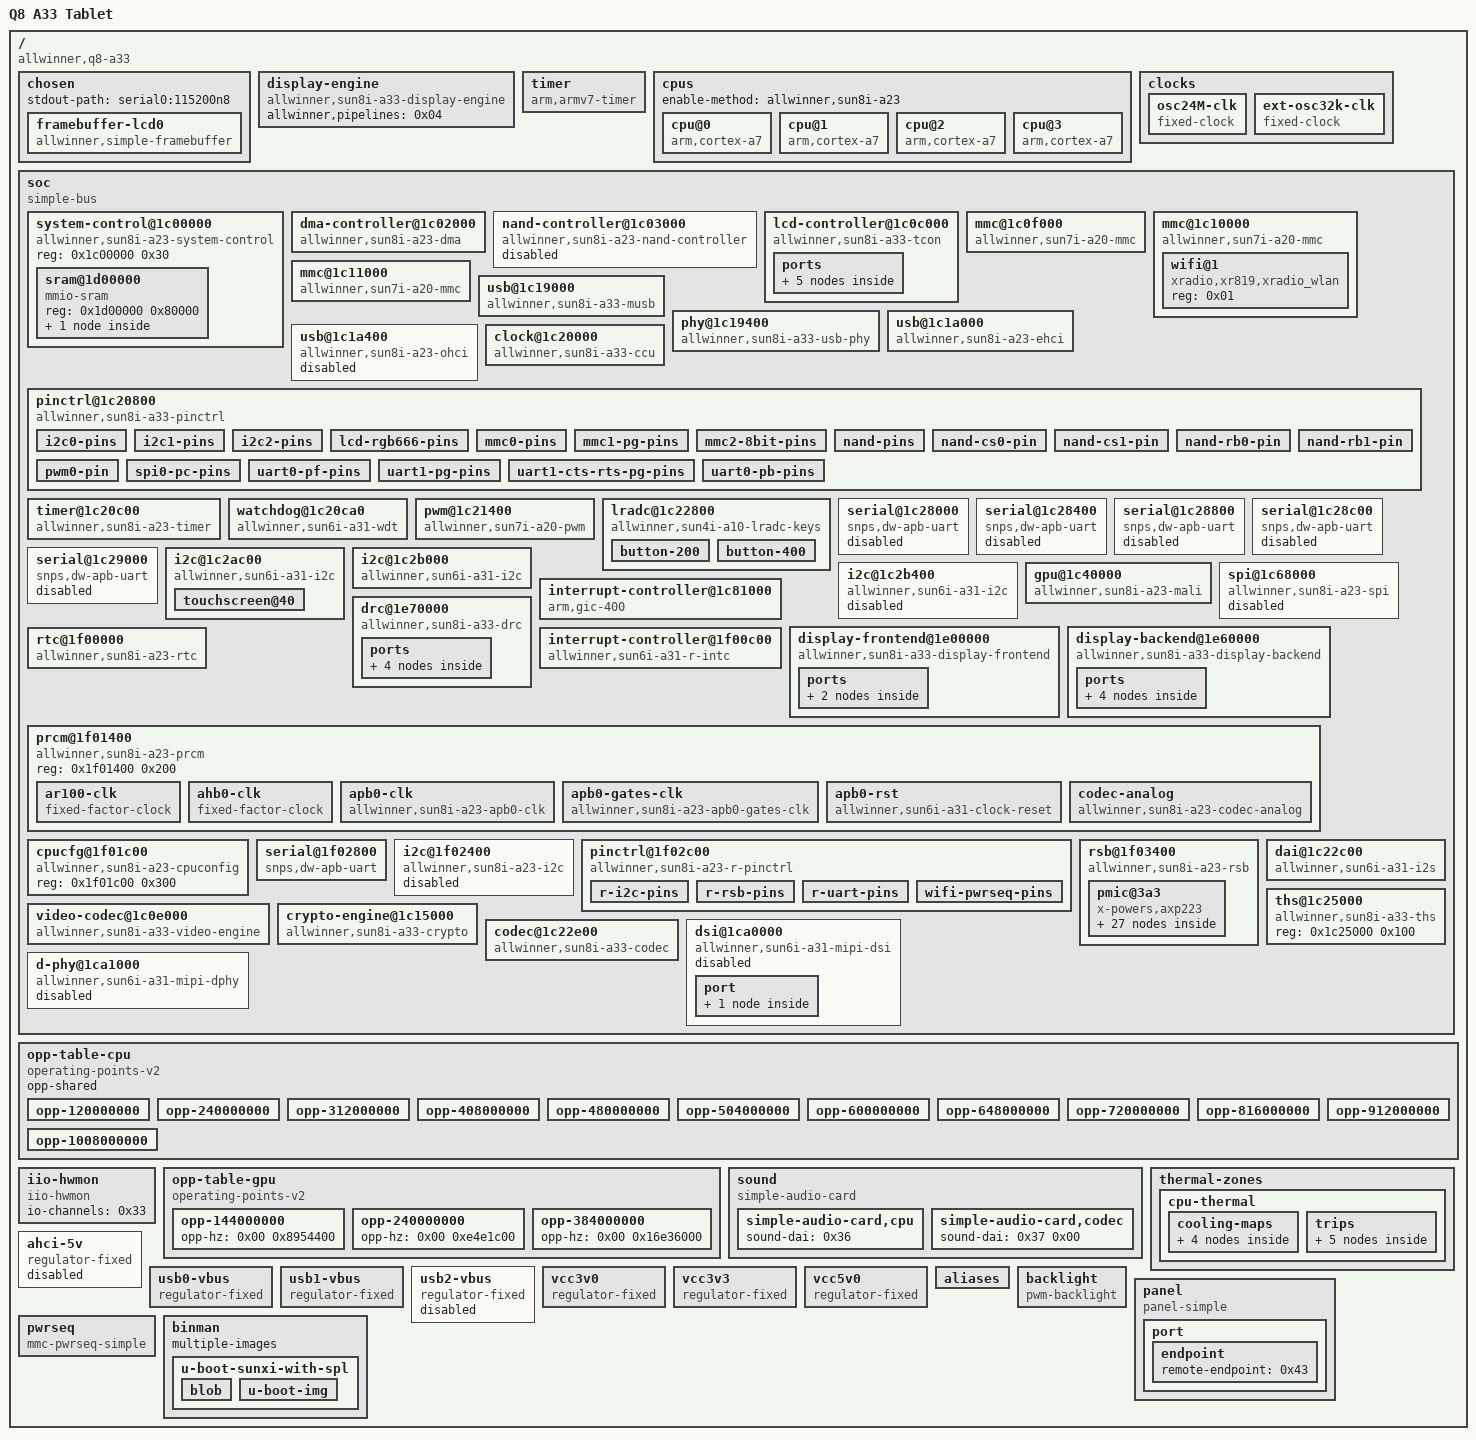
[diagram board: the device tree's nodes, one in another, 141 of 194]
/dts-v1/;

/ {
	interrupt-parent = <0x01>;
	#address-cells = <0x01>;
	#size-cells = <0x01>;
	model = "Q8 A33 Tablet";
	compatible = "allwinner,q8-a33", "allwinner,sun8i-a33";

	chosen {
		#address-cells = <0x01>;
		#size-cells = <0x01>;
		ranges;
		stdout-path = "serial0:115200n8";

		framebuffer-lcd0 {
			compatible = "allwinner,simple-framebuffer", "simple-framebuffer";
			allwinner,pipeline = "de_be0-lcd0";
			clocks = <0x02 0x26 0x02 0x28 0x02 0x57 0x02 0x55 0x02 0x54 0x02 0x62>;
			status = "okay";
			vcc-lcd-supply = <0x03>;
			phandle = <0x45>;
		};
	};

	display-engine {
		allwinner,pipelines = <0x04>;
		status = "okay";
		compatible = "allwinner,sun8i-a33-display-engine";
		phandle = <0x46>;
	};

	timer {
		compatible = "arm,armv7-timer";
		interrupts = <0x01 0x0d 0xf08 0x01 0x0e 0xf08 0x01 0x0b 0xf08 0x01 0x0a 0xf08>;
		clock-frequency = <0x16e3600>;
		arm,cpu-registers-not-fw-configured;
	};

	cpus {
		enable-method = "allwinner,sun8i-a23";
		#address-cells = <0x01>;
		#size-cells = <0x00>;

		cpu@0 {
			compatible = "arm,cortex-a7";
			device_type = "cpu";
			reg = <0x00>;
			clocks = <0x02 0x12>;
			clock-names = "cpu";
			operating-points-v2 = <0x05>;
			#cooling-cells = <0x02>;
			cpu-supply = <0x06>;
			phandle = <0x39>;
		};

		cpu@1 {
			compatible = "arm,cortex-a7";
			device_type = "cpu";
			reg = <0x01>;
			clocks = <0x02 0x12>;
			clock-names = "cpu";
			operating-points-v2 = <0x05>;
			#cooling-cells = <0x02>;
			phandle = <0x3a>;
		};

		cpu@2 {
			compatible = "arm,cortex-a7";
			device_type = "cpu";
			reg = <0x02>;
			clocks = <0x02 0x12>;
			clock-names = "cpu";
			operating-points-v2 = <0x05>;
			#cooling-cells = <0x02>;
			phandle = <0x3b>;
		};

		cpu@3 {
			compatible = "arm,cortex-a7";
			device_type = "cpu";
			reg = <0x03>;
			clocks = <0x02 0x12>;
			clock-names = "cpu";
			operating-points-v2 = <0x05>;
			#cooling-cells = <0x02>;
			phandle = <0x3c>;
		};
	};

	clocks {
		#address-cells = <0x01>;
		#size-cells = <0x01>;
		ranges;

		osc24M-clk {
			#clock-cells = <0x00>;
			compatible = "fixed-clock";
			clock-frequency = <0x16e3600>;
			clock-accuracy = <0xc350>;
			clock-output-names = "osc24M";
			phandle = <0x18>;
		};

		ext-osc32k-clk {
			#clock-cells = <0x00>;
			compatible = "fixed-clock";
			clock-frequency = <0x8000>;
			clock-accuracy = <0xc350>;
			clock-output-names = "ext-osc32k";
			phandle = <0x25>;
		};
	};

	soc {
		compatible = "simple-bus";
		#address-cells = <0x01>;
		#size-cells = <0x01>;
		ranges;

		system-control@1c00000 {
			compatible = "allwinner,sun8i-a23-system-control";
			reg = <0x1c00000 0x30>;
			#address-cells = <0x01>;
			#size-cells = <0x01>;
			ranges;

			sram@1d00000 {
				compatible = "mmio-sram";
				reg = <0x1d00000 0x80000>;
				#address-cells = <0x01>;
				#size-cells = <0x01>;
				ranges = <0x00 0x1d00000 0x80000>;
				phandle = <0x47>;

				sram-section@0 {
					compatible = "allwinner,sun8i-a23-sram-c1", "allwinner,sun4i-a10-sram-c1";
					reg = <0x00 0x80000>;
					phandle = <0x30>;
				};
			};
		};

		dma-controller@1c02000 {
			compatible = "allwinner,sun8i-a23-dma";
			reg = <0x1c02000 0x1000>;
			interrupts = <0x00 0x32 0x04>;
			clocks = <0x02 0x19>;
			resets = <0x02 0x06>;
			#dma-cells = <0x01>;
			phandle = <0x07>;
		};

		nand-controller@1c03000 {
			compatible = "allwinner,sun8i-a23-nand-controller";
			reg = <0x1c03000 0x1000>;
			interrupts = <0x00 0x46 0x04>;
			clocks = <0x02 0x1d 0x02 0x3b>;
			clock-names = "ahb", "mod";
			resets = <0x02 0x0a>;
			reset-names = "ahb";
			dmas = <0x07 0x05>;
			dma-names = "rxtx";
			pinctrl-names = "default";
			pinctrl-0 = <0x08 0x09 0x0a>;
			status = "disabled";
			#address-cells = <0x01>;
			#size-cells = <0x00>;
			phandle = <0x48>;
		};

		lcd-controller@1c0c000 {
			reg = <0x1c0c000 0x1000>;
			interrupts = <0x00 0x56 0x04>;
			dmas = <0x07 0x0c>;
			clocks = <0x02 0x26 0x02 0x57 0x02 0x0d>;
			clock-names = "ahb", "tcon-ch0", "tcon-ch1";
			clock-output-names = "tcon-data-clock";
			#clock-cells = <0x00>;
			resets = <0x02 0x13 0x02 0x1c>;
			reset-names = "lcd";
			status = "okay";
			compatible = "allwinner,sun8i-a33-tcon";
			pinctrl-names = "default";
			pinctrl-0 = <0x0b>;
			phandle = <0x49>;

			ports {
				#address-cells = <0x01>;
				#size-cells = <0x00>;

				port@0 {
					reg = <0x00>;
					phandle = <0x4a>;

					endpoint {
						remote-endpoint = <0x0c>;
						phandle = <0x24>;
					};
				};

				port@1 {
					reg = <0x01>;
					#address-cells = <0x01>;
					#size-cells = <0x00>;
					phandle = <0x4b>;

					endpoint@1 {
						reg = <0x01>;
						remote-endpoint = <0x0d>;
						phandle = <0x32>;
					};

					endpoint@0 {
						reg = <0x00>;
						remote-endpoint = <0x0e>;
						phandle = <0x43>;
					};
				};
			};
		};

		mmc@1c0f000 {
			compatible = "allwinner,sun7i-a20-mmc";
			reg = <0x1c0f000 0x1000>;
			clocks = <0x02 0x1a 0x02 0x3c 0x02 0x3e 0x02 0x3d>;
			clock-names = "ahb", "mmc", "output", "sample";
			resets = <0x02 0x07>;
			reset-names = "ahb";
			interrupts = <0x00 0x3c 0x04>;
			pinctrl-names = "default";
			pinctrl-0 = <0x0f>;
			status = "okay";
			#address-cells = <0x01>;
			#size-cells = <0x00>;
			vmmc-supply = <0x10>;
			bus-width = <0x04>;
			cd-gpios = <0x11 0x01 0x04 0x01>;
			phandle = <0x4c>;
		};

		mmc@1c10000 {
			compatible = "allwinner,sun7i-a20-mmc";
			reg = <0x1c10000 0x1000>;
			clocks = <0x02 0x1b 0x02 0x3f 0x02 0x41 0x02 0x40>;
			clock-names = "ahb", "mmc", "output", "sample";
			resets = <0x02 0x08>;
			reset-names = "ahb";
			interrupts = <0x00 0x3d 0x04>;
			status = "okay";
			#address-cells = <0x01>;
			#size-cells = <0x00>;
			pinctrl-names = "default";
			pinctrl-0 = <0x12>;
			vmmc-supply = <0x13>;
			mmc-pwrseq = <0x14>;
			bus-width = <0x04>;
			non-removable;
			phandle = <0x4d>;

      wifi@1 {
        reg = <0x01>;
        compatible = "xradio,xr819,xradio_wlan";
				phandle = <0x4e>;
      };
		};

		mmc@1c11000 {
			compatible = "allwinner,sun7i-a20-mmc";
			reg = <0x1c11000 0x1000>;
			clocks = <0x02 0x1c 0x02 0x42 0x02 0x44 0x02 0x43>;
			clock-names = "ahb", "mmc", "output", "sample";
			resets = <0x02 0x09>;
			reset-names = "ahb";
			interrupts = <0x00 0x3e 0x04>;
			status = "okay";
			#address-cells = <0x01>;
			#size-cells = <0x00>;
			phandle = <0x4f>;
		};

		usb@1c19000 {
			reg = <0x1c19000 0x400>;
			clocks = <0x02 0x22>;
			resets = <0x02 0x0f>;
			interrupts = <0x00 0x47 0x04>;
			interrupt-names = "mc";
			phys = <0x15 0x00>;
			phy-names = "usb";
			extcon = <0x15 0x00>;
			dr_mode = "otg";
			status = "okay";
			compatible = "allwinner,sun8i-a33-musb";
			phandle = <0x50>;
		};

		phy@1c19400 {
			clocks = <0x02 0x4a 0x02 0x4b>;
			clock-names = "usb0_phy", "usb1_phy";
			resets = <0x02 0x00 0x02 0x01>;
			reset-names = "usb0_reset", "usb1_reset";
			status = "okay";
			#phy-cells = <0x01>;
			compatible = "allwinner,sun8i-a33-usb-phy";
			reg = <0x1c19400 0x14 0x1c1a800 0x04>;
			reg-names = "phy_ctrl", "pmu1";
			usb0_vbus-supply = <0x17>;
			usb1_vbus-supply = <0x13>;
			phandle = <0x15>;
		};

		usb@1c1a000 {
			compatible = "allwinner,sun8i-a23-ehci", "generic-ehci";
			reg = <0x1c1a000 0x100>;
			interrupts = <0x00 0x48 0x04>;
			clocks = <0x02 0x23>;
			resets = <0x02 0x10>;
			phys = <0x15 0x01>;
			phy-names = "usb";
			status = "okay";
			phandle = <0x51>;
		};

		usb@1c1a400 {
			compatible = "allwinner,sun8i-a23-ohci", "generic-ohci";
			reg = <0x1c1a400 0x100>;
			interrupts = <0x00 0x49 0x04>;
			clocks = <0x02 0x24 0x02 0x4e>;
			resets = <0x02 0x11>;
			phys = <0x15 0x01>;
			phy-names = "usb";
			status = "disabled";
			phandle = <0x52>;
		};

		clock@1c20000 {
			reg = <0x1c20000 0x400>;
			clocks = <0x18 0x19 0x00>;
			clock-names = "hosc", "losc";
			#clock-cells = <0x01>;
			#reset-cells = <0x01>;
			compatible = "allwinner,sun8i-a33-ccu";
			phandle = <0x02>;
		};

		pinctrl@1c20800 {
			reg = <0x1c20800 0x400>;
			clocks = <0x02 0x30 0x18 0x19 0x00>;
			clock-names = "apb", "hosc", "losc";
			gpio-controller;
			interrupt-controller;
			#interrupt-cells = <0x03>;
			#gpio-cells = <0x03>;
			compatible = "allwinner,sun8i-a33-pinctrl";
			interrupts = <0x00 0x0f 0x04 0x00 0x11 0x04>;
			phandle = <0x11>;

			i2c0-pins {
				pins = "PH2", "PH3";
				function = "i2c0";
				phandle = <0x1c>;
			};

			i2c1-pins {
				pins = "PH4", "PH5";
				function = "i2c1";
				phandle = <0x1d>;
			};

			i2c2-pins {
				pins = "PE12", "PE13";
				function = "i2c2";
				phandle = <0x1e>;
			};

			lcd-rgb666-pins {
				pins = "PD2", "PD3", "PD4", "PD5", "PD6", "PD7", "PD10", "PD11", "PD12", "PD13", "PD14", "PD15", "PD18", "PD19", "PD20", "PD21", "PD22", "PD23", "PD24", "PD25", "PD26", "PD27";
				function = "lcd0";
				phandle = <0x0b>;
			};

			mmc0-pins {
				pins = "PF0", "PF1", "PF2", "PF3", "PF4", "PF5";
				function = "mmc0";
				drive-strength = <0x1e>;
				bias-pull-up;
				phandle = <0x0f>;
			};

			mmc1-pg-pins {
				pins = "PG0", "PG1", "PG2", "PG3", "PG4", "PG5";
				function = "mmc1";
				drive-strength = <0x1e>;
				bias-pull-up;
				phandle = <0x12>;
			};

			mmc2-8bit-pins {
				pins = "PC5", "PC6", "PC8", "PC9", "PC10", "PC11", "PC12", "PC13", "PC14", "PC15", "PC16";
				function = "mmc2";
				drive-strength = <0x1e>;
				bias-pull-up;
				phandle = <0x53>;
			};

			nand-pins {
				pins = "PC0", "PC1", "PC2", "PC5", "PC8", "PC9", "PC10", "PC11", "PC12", "PC13", "PC14", "PC15";
				function = "nand0";
				phandle = <0x08>;
			};

			nand-cs0-pin {
				pins = "PC4";
				function = "nand0";
				bias-pull-up;
				phandle = <0x09>;
			};

			nand-cs1-pin {
				pins = "PC3";
				function = "nand0";
				bias-pull-up;
				phandle = <0x54>;
			};

			nand-rb0-pin {
				pins = "PC6";
				function = "nand0";
				bias-pull-up;
				phandle = <0x0a>;
			};

			nand-rb1-pin {
				pins = "PC7";
				function = "nand0";
				bias-pull-up;
				phandle = <0x55>;
			};

			pwm0-pin {
				pins = "PH0";
				function = "pwm0";
				phandle = <0x1a>;
			};

			spi0-pc-pins {
				pins = "PC0", "PC1", "PC2", "PC3";
				function = "spi0";
				phandle = <0x56>;
			};

			uart0-pf-pins {
				pins = "PF2", "PF4";
				function = "uart0";
				phandle = <0x57>;
			};

			uart1-pg-pins {
				pins = "PG6", "PG7";
				function = "uart1";
				phandle = <0x58>;
			};

			uart1-cts-rts-pg-pins {
				pins = "PG8", "PG9";
				function = "uart1";
				phandle = <0x59>;
			};

			uart0-pb-pins {
				pins = "PB0", "PB1";
				function = "uart0";
				phandle = <0x5a>;
			};
		};

		timer@1c20c00 {
			compatible = "allwinner,sun8i-a23-timer";
			reg = <0x1c20c00 0xa0>;
			interrupts = <0x00 0x12 0x04 0x00 0x13 0x04>;
			clocks = <0x18>;
		};

		watchdog@1c20ca0 {
			compatible = "allwinner,sun6i-a31-wdt";
			reg = <0x1c20ca0 0x20>;
			interrupts = <0x00 0x19 0x04>;
			clocks = <0x18>;
			phandle = <0x5b>;
		};

		pwm@1c21400 {
			compatible = "allwinner,sun7i-a20-pwm";
			reg = <0x1c21400 0x0c>;
			clocks = <0x18>;
			#pwm-cells = <0x03>;
			status = "okay";
			pinctrl-names = "default";
			pinctrl-0 = <0x1a>;
			phandle = <0x41>;
		};

		lradc@1c22800 {
			compatible = "allwinner,sun4i-a10-lradc-keys";
			reg = <0x1c22800 0x100>;
			interrupts = <0x00 0x1e 0x04>;
			status = "okay";
			vref-supply = <0x1b>;
			phandle = <0x5c>;

			button-200 {
				label = "Volume Up";
				linux,code = <0x73>;
				channel = <0x00>;
				voltage = <0x30d40>;
			};

			button-400 {
				label = "Volume Down";
				linux,code = <0x72>;
				channel = <0x00>;
				voltage = <0x61a80>;
			};
		};

		serial@1c28000 {
			compatible = "snps,dw-apb-uart";
			reg = <0x1c28000 0x400>;
			interrupts = <0x00 0x00 0x04>;
			reg-shift = <0x02>;
			reg-io-width = <0x04>;
			clocks = <0x02 0x36>;
			resets = <0x02 0x23>;
			dmas = <0x07 0x06 0x07 0x06>;
			dma-names = "tx", "rx";
			status = "disabled";
			phandle = <0x5d>;
		};

		serial@1c28400 {
			compatible = "snps,dw-apb-uart";
			reg = <0x1c28400 0x400>;
			interrupts = <0x00 0x01 0x04>;
			reg-shift = <0x02>;
			reg-io-width = <0x04>;
			clocks = <0x02 0x37>;
			resets = <0x02 0x24>;
			dmas = <0x07 0x07 0x07 0x07>;
			dma-names = "tx", "rx";
			status = "disabled";
			phandle = <0x5e>;
		};

		serial@1c28800 {
			compatible = "snps,dw-apb-uart";
			reg = <0x1c28800 0x400>;
			interrupts = <0x00 0x02 0x04>;
			reg-shift = <0x02>;
			reg-io-width = <0x04>;
			clocks = <0x02 0x38>;
			resets = <0x02 0x25>;
			dmas = <0x07 0x08 0x07 0x08>;
			dma-names = "tx", "rx";
			status = "disabled";
			phandle = <0x5f>;
		};

		serial@1c28c00 {
			compatible = "snps,dw-apb-uart";
			reg = <0x1c28c00 0x400>;
			interrupts = <0x00 0x03 0x04>;
			reg-shift = <0x02>;
			reg-io-width = <0x04>;
			clocks = <0x02 0x39>;
			resets = <0x02 0x26>;
			dmas = <0x07 0x09 0x07 0x09>;
			dma-names = "tx", "rx";
			status = "enabled";
			phandle = <0x60>;
		};

		serial@1c29000 {
			compatible = "snps,dw-apb-uart";
			reg = <0x1c29000 0x400>;
			interrupts = <0x00 0x04 0x04>;
			reg-shift = <0x02>;
			reg-io-width = <0x04>;
			clocks = <0x02 0x3a>;
			resets = <0x02 0x27>;
			dmas = <0x07 0x0a 0x07 0x0a>;
			dma-names = "tx", "rx";
			status = "disabled";
			phandle = <0x61>;
		};

		i2c@1c2ac00 {
			compatible = "allwinner,sun6i-a31-i2c";
			reg = <0x1c2ac00 0x400>;
			interrupts = <0x00 0x06 0x04>;
			clocks = <0x02 0x33>;
			resets = <0x02 0x20>;
			pinctrl-names = "default";
			pinctrl-0 = <0x1c>;
			status = "okay";
			#address-cells = <0x01>;
			#size-cells = <0x00>;
			clock-frequency = <0x61a80>;
			phandle = <0x62>;

			touchscreen@40 {
				reg = <0x40>;
				interrupt-parent = <0x11>;
				interrupts = <0x01 0x05 0x02>;
				power-gpios = <0x11 0x07 0x01 0x00>;
				status = "okay";
				phandle = <0x63>;
			};
		};

		i2c@1c2b000 {
			compatible = "allwinner,sun6i-a31-i2c";
			reg = <0x1c2b000 0x400>;
			interrupts = <0x00 0x07 0x04>;
			clocks = <0x02 0x34>;
			resets = <0x02 0x21>;
			pinctrl-names = "default";
			pinctrl-0 = <0x1d>;
			status = "okay";
			#address-cells = <0x01>;
			#size-cells = <0x00>;
			phandle = <0x64>;
		};

		i2c@1c2b400 {
			compatible = "allwinner,sun6i-a31-i2c";
			reg = <0x1c2b400 0x400>;
			interrupts = <0x00 0x08 0x04>;
			clocks = <0x02 0x35>;
			resets = <0x02 0x22>;
			pinctrl-names = "default";
			pinctrl-0 = <0x1e>;
			status = "disabled";
			#address-cells = <0x01>;
			#size-cells = <0x00>;
			phandle = <0x65>;
		};

		gpu@1c40000 {
			compatible = "allwinner,sun8i-a23-mali", "allwinner,sun7i-a20-mali", "arm,mali-400";
			reg = <0x1c40000 0x10000>;
			interrupts = <0x00 0x61 0x04 0x00 0x62 0x04 0x00 0x63 0x04 0x00 0x64 0x04 0x00 0x66 0x04 0x00 0x67 0x04 0x00 0x65 0x04>;
			interrupt-names = "gp", "gpmmu", "pp0", "ppmmu0", "pp1", "ppmmu1", "pmu";
			clocks = <0x02 0x2a 0x02 0x63>;
			clock-names = "bus", "core";
			resets = <0x02 0x17>;
			#cooling-cells = <0x02>;
			assigned-clocks = <0x02 0x63>;
			assigned-clock-rates = <0x16e36000>;
			operating-points-v2 = <0x1f>;
			phandle = <0x3f>;
		};

		spi@1c68000 {
			compatible = "allwinner,sun8i-a23-spi", "allwinner,sun8i-h3-spi";
			reg = <0x1c68000 0x1000>;
			interrupts = <0x00 0x41 0x04>;
			clocks = <0x02 0x20 0x02 0x46>;
			clock-names = "ahb", "mod";
			dmas = <0x07 0x17 0x07 0x17>;
			dma-names = "rx", "tx";
			resets = <0x02 0x0d>;
			status = "disabled";
			#address-cells = <0x01>;
			#size-cells = <0x00>;
			phandle = <0x66>;
		};

		interrupt-controller@1c81000 {
			compatible = "arm,gic-400";
			reg = <0x1c81000 0x1000 0x1c82000 0x2000 0x1c84000 0x2000 0x1c86000 0x2000>;
			interrupt-controller;
			#interrupt-cells = <0x03>;
			interrupts = <0x01 0x09 0xf04>;
			phandle = <0x01>;
		};

		display-frontend@1e00000 {
			reg = <0x1e00000 0x20000>;
			interrupts = <0x00 0x5d 0x04>;
			clocks = <0x02 0x29 0x02 0x56 0x02 0x53>;
			clock-names = "ahb", "mod", "ram";
			resets = <0x02 0x16>;
			compatible = "allwinner,sun8i-a33-display-frontend";
			phandle = <0x04>;

			ports {
				#address-cells = <0x01>;
				#size-cells = <0x00>;

				port@1 {
					reg = <0x01>;
					phandle = <0x67>;

					endpoint {
						remote-endpoint = <0x20>;
						phandle = <0x21>;
					};
				};
			};
		};

		display-backend@1e60000 {
			reg = <0x1e60000 0x10000 0x1e80000 0x1000>;
			interrupts = <0x00 0x5f 0x04>;
			clocks = <0x02 0x28 0x02 0x55 0x02 0x54 0x02 0x2e>;
			clock-names = "ahb", "mod", "ram", "sat";
			resets = <0x02 0x15 0x02 0x1b>;
			compatible = "allwinner,sun8i-a33-display-backend";
			reg-names = "be", "sat";
			reset-names = "be", "sat";
			phandle = <0x68>;

			ports {
				#address-cells = <0x01>;
				#size-cells = <0x00>;

				port@0 {
					reg = <0x00>;
					phandle = <0x69>;

					endpoint {
						remote-endpoint = <0x21>;
						phandle = <0x20>;
					};
				};

				port@1 {
					reg = <0x01>;
					phandle = <0x6a>;

					endpoint {
						remote-endpoint = <0x22>;
						phandle = <0x23>;
					};
				};
			};
		};

		drc@1e70000 {
			reg = <0x1e70000 0x10000>;
			interrupts = <0x00 0x5b 0x04>;
			clocks = <0x02 0x2d 0x02 0x62 0x02 0x52>;
			clock-names = "ahb", "mod", "ram";
			resets = <0x02 0x1a>;
			compatible = "allwinner,sun8i-a33-drc";
			phandle = <0x6b>;

			ports {
				#address-cells = <0x01>;
				#size-cells = <0x00>;

				port@0 {
					reg = <0x00>;
					phandle = <0x6c>;

					endpoint {
						remote-endpoint = <0x23>;
						phandle = <0x22>;
					};
				};

				port@1 {
					reg = <0x01>;
					phandle = <0x6d>;

					endpoint {
						remote-endpoint = <0x24>;
						phandle = <0x0c>;
					};
				};
			};
		};

		rtc@1f00000 {
			compatible = "allwinner,sun8i-a23-rtc";
			reg = <0x1f00000 0x400>;
			interrupts = <0x00 0x28 0x04 0x00 0x29 0x04>;
			clock-output-names = "osc32k", "osc32k-out";
			clocks = <0x25>;
			#clock-cells = <0x01>;
			phandle = <0x19>;
		};

		interrupt-controller@1f00c00 {
			compatible = "allwinner,sun6i-a31-r-intc";
			interrupt-controller;
			#interrupt-cells = <0x02>;
			reg = <0x1f00c00 0x400>;
			interrupts = <0x00 0x20 0x04>;
			phandle = <0x2e>;
		};

		prcm@1f01400 {
			compatible = "allwinner,sun8i-a23-prcm";
			reg = <0x1f01400 0x200>;

			ar100-clk {
				compatible = "fixed-factor-clock";
				#clock-cells = <0x00>;
				clock-div = <0x01>;
				clock-mult = <0x01>;
				clocks = <0x18>;
				clock-output-names = "ar100";
				phandle = <0x26>;
			};

			ahb0-clk {
				compatible = "fixed-factor-clock";
				#clock-cells = <0x00>;
				clock-div = <0x01>;
				clock-mult = <0x01>;
				clocks = <0x26>;
				clock-output-names = "ahb0";
				phandle = <0x27>;
			};

			apb0-clk {
				compatible = "allwinner,sun8i-a23-apb0-clk";
				#clock-cells = <0x00>;
				clocks = <0x27>;
				clock-output-names = "apb0";
				phandle = <0x28>;
			};

			apb0-gates-clk {
				compatible = "allwinner,sun8i-a23-apb0-gates-clk";
				#clock-cells = <0x01>;
				clocks = <0x28>;
				clock-output-names = "apb0_pio", "apb0_timer", "apb0_rsb", "apb0_uart", "apb0_i2c";
				phandle = <0x29>;
			};

			apb0-rst {
				compatible = "allwinner,sun6i-a31-clock-reset";
				#reset-cells = <0x01>;
				phandle = <0x2a>;
			};

			codec-analog {
				compatible = "allwinner,sun8i-a23-codec-analog";
				phandle = <0x35>;
			};
		};

		cpucfg@1f01c00 {
			compatible = "allwinner,sun8i-a23-cpuconfig";
			reg = <0x1f01c00 0x300>;
		};

		serial@1f02800 {
			compatible = "snps,dw-apb-uart";
			reg = <0x1f02800 0x400>;
			interrupts = <0x00 0x26 0x04>;
			reg-shift = <0x02>;
			reg-io-width = <0x04>;
			clocks = <0x29 0x04>;
			resets = <0x2a 0x04>;
			status = "okay";
			pinctrl-names = "default";
			pinctrl-0 = <0x2b>;
			phandle = <0x6e>;
		};

		i2c@1f02400 {
			compatible = "allwinner,sun8i-a23-i2c", "allwinner,sun6i-a31-i2c";
			reg = <0x1f02400 0x400>;
			interrupts = <0x00 0x2c 0x04>;
			pinctrl-names = "default";
			pinctrl-0 = <0x2c>;
			clocks = <0x29 0x06>;
			resets = <0x2a 0x06>;
			status = "disabled";
			#address-cells = <0x01>;
			#size-cells = <0x00>;
			phandle = <0x6f>;
		};

		pinctrl@1f02c00 {
			compatible = "allwinner,sun8i-a23-r-pinctrl";
			reg = <0x1f02c00 0x400>;
			interrupts = <0x00 0x2d 0x04>;
			clocks = <0x29 0x00 0x18 0x19 0x00>;
			clock-names = "apb", "hosc", "losc";
			gpio-controller;
			interrupt-controller;
			#interrupt-cells = <0x03>;
			#gpio-cells = <0x03>;
			phandle = <0x70>;

			r-i2c-pins {
				pins = "PL0", "PL1";
				function = "s_i2c";
				bias-pull-up;
				phandle = <0x2c>;
			};

			r-rsb-pins {
				pins = "PL0", "PL1";
				function = "s_rsb";
				drive-strength = <0x14>;
				bias-pull-up;
				phandle = <0x2d>;
			};

			r-uart-pins {
				pins = "PL2", "PL3";
				function = "s_uart";
				phandle = <0x2b>;
			};

			wifi-pwrseq-pins {
				pins = "PL6", "PL7", "PL11";
				function = "gpio_in";
				bias-pull-up;
				phandle = <0x44>;
			};
		};

		rsb@1f03400 {
			compatible = "allwinner,sun8i-a23-rsb";
			reg = <0x1f03400 0x400>;
			interrupts = <0x00 0x27 0x04>;
			clocks = <0x29 0x03>;
			clock-frequency = <0x2dc6c0>;
			resets = <0x2a 0x03>;
			pinctrl-names = "default";
			pinctrl-0 = <0x2d>;
			status = "okay";
			#address-cells = <0x01>;
			#size-cells = <0x00>;
			phandle = <0x71>;

			pmic@3a3 {
				compatible = "x-powers,axp223";
				reg = <0x3a3>;
				interrupt-parent = <0x2e>;
				interrupts = <0x00 0x08>;
				eldoin-supply = <0x10>;
				drivevbus-supply = <0x2f>;
				x-powers,drive-vbus-en;
				interrupt-controller;
				#interrupt-cells = <0x01>;
				phandle = <0x72>;

				ac-power {
					compatible = "x-powers,axp221-ac-power-supply";
					status = "okay";
					phandle = <0x73>;
				};

				adc {
					compatible = "x-powers,axp221-adc";
					#io-channel-cells = <0x01>;
					phandle = <0x74>;
				};

				battery-power {
					compatible = "x-powers,axp221-battery-power-supply";
					status = "okay";
					phandle = <0x75>;
				};

				gpio {
					compatible = "x-powers,axp221-gpio";
					gpio-controller;
					#gpio-cells = <0x02>;
					phandle = <0x76>;
				};

				regulators {
					x-powers,dcdc-freq = <0xbb8>;

					dcdc1 {
						regulator-name = "vcc-3v0";
						regulator-always-on;
						regulator-min-microvolt = <0x2dc6c0>;
						regulator-max-microvolt = <0x2dc6c0>;
						phandle = <0x10>;
					};

					dcdc2 {
						regulator-name = "vdd-sys";
						regulator-always-on;
						regulator-min-microvolt = <0xdbba0>;
						regulator-max-microvolt = <0x155cc0>;
						phandle = <0x06>;
					};

					dcdc3 {
						regulator-name = "vdd-cpu";
						regulator-always-on;
						regulator-min-microvolt = <0xdbba0>;
						regulator-max-microvolt = <0x155cc0>;
						phandle = <0x77>;
					};

					dcdc4 {
						regulator-name = "dcdc4";
						phandle = <0x78>;
					};

					dcdc5 {
						regulator-name = "vcc-dram";
						regulator-always-on;
						regulator-min-microvolt = <0x16e360>;
						regulator-max-microvolt = <0x16e360>;
						phandle = <0x79>;
					};

					dc1sw {
						regulator-name = "vcc-lcd";
						phandle = <0x03>;
					};

					dc5ldo {
						regulator-name = "vdd-cpus";
						regulator-always-on;
						regulator-min-microvolt = <0xdbba0>;
						regulator-max-microvolt = <0x155cc0>;
						phandle = <0x7a>;
					};

					aldo1 {
						regulator-name = "vcc-io";
						regulator-always-on;
						regulator-min-microvolt = <0x2dc6c0>;
						regulator-max-microvolt = <0x2dc6c0>;
						phandle = <0x7b>;
					};

					aldo2 {
						regulator-name = "vdd-dll";
						regulator-always-on;
						regulator-min-microvolt = <0x23dbb0>;
						regulator-max-microvolt = <0x286f90>;
						phandle = <0x7c>;
					};

					aldo3 {
						regulator-name = "vcc-pll-avcc";
						regulator-always-on;
						regulator-min-microvolt = <0x2932e0>;
						regulator-max-microvolt = <0x325aa0>;
						phandle = <0x7d>;
					};

					dldo1 {
						regulator-name = "vcc-wifi";
						regulator-always-on;
						regulator-min-microvolt = <0x325aa0>;
						regulator-max-microvolt = <0x325aa0>;
						phandle = <0x13>;
					};

					dldo2 {
						regulator-name = "dldo2";
						phandle = <0x7e>;
					};

					dldo3 {
						regulator-name = "dldo3";
						phandle = <0x7f>;
					};

					dldo4 {
						regulator-name = "dldo4";
						phandle = <0x80>;
					};

					eldo1 {
						regulator-name = "eldo1";
						phandle = <0x81>;
					};

					eldo2 {
						regulator-name = "eldo2";
						phandle = <0x82>;
					};

					eldo3 {
						regulator-name = "eldo3";
						phandle = <0x83>;
					};

					ldo_io0 {
						regulator-name = "ldo_io0";
						status = "disabled";
						phandle = <0x84>;
					};

					ldo_io1 {
						regulator-name = "vcc-touchscreen";
						status = "okay";
						regulator-min-microvolt = <0x325aa0>;
						regulator-max-microvolt = <0x325aa0>;
						phandle = <0x85>;
					};

					rtc_ldo {
						regulator-always-on;
						regulator-min-microvolt = <0x2dc6c0>;
						regulator-max-microvolt = <0x2dc6c0>;
						regulator-name = "vcc-rtc";
						phandle = <0x86>;
					};

					drivevbus {
						regulator-name = "usb0-vbus";
						status = "okay";
						phandle = <0x17>;
					};
				};

				usb-power {
					compatible = "x-powers,axp223-usb-power-supply";
					status = "okay";
					phandle = <0x16>;
				};
			};
		};

		video-codec@1c0e000 {
			compatible = "allwinner,sun8i-a33-video-engine";
			reg = <0x1c0e000 0x1000>;
			clocks = <0x02 0x25 0x02 0x5b 0x02 0x50>;
			clock-names = "ahb", "mod", "ram";
			resets = <0x02 0x12>;
			interrupts = <0x00 0x3a 0x04>;
			allwinner,sram = <0x30 0x01>;
		};

		crypto-engine@1c15000 {
			compatible = "allwinner,sun8i-a33-crypto";
			reg = <0x1c15000 0x1000>;
			interrupts = <0x00 0x50 0x04>;
			clocks = <0x02 0x18 0x02 0x45>;
			clock-names = "ahb", "mod";
			resets = <0x02 0x05>;
			reset-names = "ahb";
			phandle = <0x87>;
		};

		dai@1c22c00 {
			#sound-dai-cells = <0x00>;
			compatible = "allwinner,sun6i-a31-i2s";
			reg = <0x1c22c00 0x200>;
			interrupts = <0x00 0x1d 0x04>;
			clocks = <0x02 0x2f 0x02 0x5c>;
			clock-names = "apb", "mod";
			resets = <0x02 0x1d>;
			dmas = <0x07 0x0f 0x07 0x0f>;
			dma-names = "rx", "tx";
			status = "okay";
			phandle = <0x36>;
		};

		codec@1c22e00 {
			#sound-dai-cells = <0x01>;
			compatible = "allwinner,sun8i-a33-codec";
			reg = <0x1c22e00 0x400>;
			interrupts = <0x00 0x1d 0x04>;
			clocks = <0x02 0x2f 0x02 0x5c>;
			clock-names = "bus", "mod";
			status = "okay";
			phandle = <0x37>;
		};

		ths@1c25000 {
			compatible = "allwinner,sun8i-a33-ths";
			reg = <0x1c25000 0x100>;
			#thermal-sensor-cells = <0x00>;
			#io-channel-cells = <0x00>;
			phandle = <0x33>;
		};

		dsi@1ca0000 {
			compatible = "allwinner,sun6i-a31-mipi-dsi";
			reg = <0x1ca0000 0x1000>;
			interrupts = <0x00 0x59 0x04>;
			clocks = <0x02 0x17 0x02 0x60>;
			clock-names = "bus", "mod";
			resets = <0x02 0x04>;
			phys = <0x31>;
			phy-names = "dphy";
			status = "disabled";
			#address-cells = <0x01>;
			#size-cells = <0x00>;
			phandle = <0x88>;

			port {

				endpoint {
					remote-endpoint = <0x32>;
					phandle = <0x0d>;
				};
			};
		};

		d-phy@1ca1000 {
			compatible = "allwinner,sun6i-a31-mipi-dphy";
			reg = <0x1ca1000 0x1000>;
			interrupts = <0x00 0x59 0x04>;
			clocks = <0x02 0x17 0x02 0x61>;
			clock-names = "bus", "mod";
			resets = <0x02 0x04>;
			status = "disabled";
			#phy-cells = <0x00>;
			phandle = <0x31>;
		};
	};

	opp-table-cpu {
		compatible = "operating-points-v2";
		opp-shared;
		phandle = <0x05>;

		opp-120000000 {
			opp-hz = <0x00 0x7270e00>;
			opp-microvolt = <0xfde80>;
			clock-latency-ns = <0x3b9b0>;
		};

		opp-240000000 {
			opp-hz = <0x00 0xe4e1c00>;
			opp-microvolt = <0xfde80>;
			clock-latency-ns = <0x3b9b0>;
		};

		opp-312000000 {
			opp-hz = <0x00 0x1298be00>;
			opp-microvolt = <0xfde80>;
			clock-latency-ns = <0x3b9b0>;
		};

		opp-408000000 {
			opp-hz = <0x00 0x18519600>;
			opp-microvolt = <0xfde80>;
			clock-latency-ns = <0x3b9b0>;
		};

		opp-480000000 {
			opp-hz = <0x00 0x1c9c3800>;
			opp-microvolt = <0xfde80>;
			clock-latency-ns = <0x3b9b0>;
		};

		opp-504000000 {
			opp-hz = <0x00 0x1e0a6e00>;
			opp-microvolt = <0xfde80>;
			clock-latency-ns = <0x3b9b0>;
		};

		opp-600000000 {
			opp-hz = <0x00 0x23c34600>;
			opp-microvolt = <0xfde80>;
			clock-latency-ns = <0x3b9b0>;
		};

		opp-648000000 {
			opp-hz = <0x00 0x269fb200>;
			opp-microvolt = <0xfde80>;
			clock-latency-ns = <0x3b9b0>;
		};

		opp-720000000 {
			opp-hz = <0x00 0x2aea5400>;
			opp-microvolt = <0x10c8e0>;
			clock-latency-ns = <0x3b9b0>;
		};

		opp-816000000 {
			opp-hz = <0x00 0x30a32c00>;
			opp-microvolt = <0x10c8e0>;
			clock-latency-ns = <0x3b9b0>;
		};

		opp-912000000 {
			opp-hz = <0x00 0x365c0400>;
			opp-microvolt = <0x124f80>;
			clock-latency-ns = <0x3b9b0>;
		};

		opp-1008000000 {
			opp-hz = <0x00 0x3c14dc00>;
			opp-microvolt = <0x124f80>;
			clock-latency-ns = <0x3b9b0>;
		};
	};

	iio-hwmon {
		compatible = "iio-hwmon";
		io-channels = <0x33>;
	};

	opp-table-gpu {
		compatible = "operating-points-v2";
		phandle = <0x1f>;

		opp-144000000 {
			opp-hz = <0x00 0x8954400>;
		};

		opp-240000000 {
			opp-hz = <0x00 0xe4e1c00>;
		};

		opp-384000000 {
			opp-hz = <0x00 0x16e36000>;
		};
	};

	sound {
		compatible = "simple-audio-card";
		simple-audio-card,name = "sun8i-a33-audio";
		simple-audio-card,format = "i2s";
		simple-audio-card,frame-master = <0x34>;
		simple-audio-card,bitclock-master = <0x34>;
		simple-audio-card,mclk-fs = <0x80>;
		simple-audio-card,aux-devs = <0x35>;
		simple-audio-card,routing = "Left DAC", "DACL", "Right DAC", "DACR";
		status = "okay";
		phandle = <0x89>;

		simple-audio-card,cpu {
			sound-dai = <0x36>;
		};

		simple-audio-card,codec {
			sound-dai = <0x37 0x00>;
			phandle = <0x34>;
		};
	};

	thermal-zones {

		cpu-thermal {
			polling-delay-passive = <0xfa>;
			polling-delay = <0x3e8>;
			thermal-sensors = <0x33>;

			cooling-maps {

				map0 {
					trip = <0x38>;
					cooling-device = <0x39 0xffffffff 0xffffffff 0x3a 0xffffffff 0xffffffff 0x3b 0xffffffff 0xffffffff 0x3c 0xffffffff 0xffffffff>;
				};

				map1 {
					trip = <0x3d>;
					cooling-device = <0x39 0xffffffff 0xffffffff 0x3a 0xffffffff 0xffffffff 0x3b 0xffffffff 0xffffffff 0x3c 0xffffffff 0xffffffff>;
				};

				map2 {
					trip = <0x3e>;
					cooling-device = <0x3f 0x01 0xffffffff>;
				};

				map3 {
					trip = <0x40>;
					cooling-device = <0x3f 0x02 0xffffffff>;
				};
			};

			trips {

				cpu-alert0 {
					temperature = <0x124f8>;
					hysteresis = <0x7d0>;
					type = "passive";
					phandle = <0x38>;
				};

				gpu-alert0 {
					temperature = <0x14c08>;
					hysteresis = <0x7d0>;
					type = "passive";
					phandle = <0x3e>;
				};

				cpu-alert1 {
					temperature = <0x15f90>;
					hysteresis = <0x7d0>;
					type = "hot";
					phandle = <0x3d>;
				};

				gpu-alert1 {
					temperature = <0x17318>;
					hysteresis = <0x7d0>;
					type = "hot";
					phandle = <0x40>;
				};

				cpu-crit {
					temperature = <0x1adb0>;
					hysteresis = <0x7d0>;
					type = "critical";
					phandle = <0x8a>;
				};
			};
		};
	};

	ahci-5v {
		compatible = "regulator-fixed";
		regulator-name = "ahci-5v";
		regulator-min-microvolt = <0x4c4b40>;
		regulator-max-microvolt = <0x4c4b40>;
		regulator-boot-on;
		enable-active-high;
		gpio = <0x11 0x01 0x08 0x00>;
		status = "disabled";
		phandle = <0x8b>;
	};

	usb0-vbus {
		compatible = "regulator-fixed";
		regulator-name = "usb0-vbus";
		regulator-min-microvolt = <0x4c4b40>;
		regulator-max-microvolt = <0x4c4b40>;
		enable-active-high;
    regulator-always-on;
		status = "okay";
		phandle = <0x8c>;
	};

	usb1-vbus {
		compatible = "regulator-fixed";
		regulator-name = "usb1-vbus";
		regulator-min-microvolt = <0x4c4b40>;
		regulator-max-microvolt = <0x4c4b40>;
		regulator-boot-on;
		enable-active-high;
    regulator-always-on;
		status = "okay";
		phandle = <0x8d>;
	};

	usb2-vbus {
		compatible = "regulator-fixed";
		regulator-name = "usb2-vbus";
		regulator-min-microvolt = <0x4c4b40>;
		regulator-max-microvolt = <0x4c4b40>;
		regulator-boot-on;
		enable-active-high;
		gpio = <0x11 0x07 0x03 0x00>;
		status = "disabled";
		phandle = <0x8e>;
	};

	vcc3v0 {
		compatible = "regulator-fixed";
		regulator-name = "vcc3v0";
		regulator-min-microvolt = <0x2dc6c0>;
		regulator-max-microvolt = <0x2dc6c0>;
		phandle = <0x1b>;
	};

	vcc3v3 {
		compatible = "regulator-fixed";
		regulator-name = "vcc3v3";
		regulator-min-microvolt = <0x325aa0>;
		regulator-max-microvolt = <0x325aa0>;
		phandle = <0x8f>;
	};

	vcc5v0 {
		compatible = "regulator-fixed";
		regulator-name = "vcc5v0";
		regulator-min-microvolt = <0x4c4b40>;
		regulator-max-microvolt = <0x4c4b40>;
		phandle = <0x2f>;
	};

	aliases {
		serial0 = "/soc/serial@1f02800";
		ethernet0 = "/soc/mmc@1c10000/wifi@1";
		mmc0 = "/soc/mmc@1c0f000";
	};

	backlight {
		compatible = "pwm-backlight";
		pwms = <0x41 0x00 0xc350 0x01>;
		brightness-levels = <0x00 0x0a 0x14 0x1e 0x28 0x32 0x3c 0x46 0x50 0x5a 0x64>;
		default-brightness-level = <0x08>;
		enable-gpios = <0x11 0x07 0x06 0x00>;
		power-supply = <0x03>;
		phandle = <0x42>;
	};

	panel {
    compatible = "panel-simple";
		backlight = <0x42>;
		enable-gpios = <0x11 0x07 0x07 0x00>;
		power-supply = <0x03>;
		phandle = <0x90>;

		port {

			endpoint {
				remote-endpoint = <0x43>;
				phandle = <0x0e>;
			};
		};
	};

	pwrseq {
		compatible = "mmc-pwrseq-simple";
		post-power-on-delay-ms = <0xc8>;
    pinctrl-names = "default";
		pinctrl-0 = <0x44>;
    //reset-gpios = <0x11 0x0b 0x07 0x01>;
		phandle = <0x14>;
	};

	binman {
		multiple-images;
		phandle = <0x91>;

		u-boot-sunxi-with-spl {
			filename = "u-boot-sunxi-with-spl.bin";
			pad-byte = <0xff>;

			blob {
				min-size = <0x8000>;
				filename = "spl/sunxi-spl.bin";
			};

			u-boot-img {
			};
		};
	};

	__symbols__ {
		simplefb_lcd = "/chosen/framebuffer-lcd0";
		de = "/display-engine";
		cpu0 = "/cpus/cpu@0";
		cpu1 = "/cpus/cpu@1";
		cpu2 = "/cpus/cpu@2";
		cpu3 = "/cpus/cpu@3";
		osc24M = "/clocks/osc24M-clk";
		ext_osc32k = "/clocks/ext-osc32k-clk";
		sram_c = "/soc/system-control@1c00000/sram@1d00000";
		ve_sram = "/soc/system-control@1c00000/sram@1d00000/sram-section@0";
		dma = "/soc/dma-controller@1c02000";
		nfc = "/soc/nand-controller@1c03000";
		tcon0 = "/soc/lcd-controller@1c0c000";
		tcon0_in = "/soc/lcd-controller@1c0c000/ports/port@0";
		tcon0_in_drc0 = "/soc/lcd-controller@1c0c000/ports/port@0/endpoint";
		tcon0_out = "/soc/lcd-controller@1c0c000/ports/port@1";
		tcon0_out_dsi = "/soc/lcd-controller@1c0c000/ports/port@1/endpoint@1";
		tcon0_out_lcd = "/soc/lcd-controller@1c0c000/ports/port@1/endpoint@0";
		mmc0 = "/soc/mmc@1c0f000";
		mmc1 = "/soc/mmc@1c10000";
		sdio_wifi = "/soc/mmc@1c10000/wifi@1";
		mmc2 = "/soc/mmc@1c11000";
		usb_otg = "/soc/usb@1c19000";
		usbphy = "/soc/phy@1c19400";
		ehci0 = "/soc/usb@1c1a000";
		ohci0 = "/soc/usb@1c1a400";
		ccu = "/soc/clock@1c20000";
		pio = "/soc/pinctrl@1c20800";
		i2c0_pins = "/soc/pinctrl@1c20800/i2c0-pins";
		i2c1_pins = "/soc/pinctrl@1c20800/i2c1-pins";
		i2c2_pins = "/soc/pinctrl@1c20800/i2c2-pins";
		lcd_rgb666_pins = "/soc/pinctrl@1c20800/lcd-rgb666-pins";
		mmc0_pins = "/soc/pinctrl@1c20800/mmc0-pins";
		mmc1_pg_pins = "/soc/pinctrl@1c20800/mmc1-pg-pins";
		mmc2_8bit_pins = "/soc/pinctrl@1c20800/mmc2-8bit-pins";
		nand_pins = "/soc/pinctrl@1c20800/nand-pins";
		nand_cs0_pin = "/soc/pinctrl@1c20800/nand-cs0-pin";
		nand_cs1_pin = "/soc/pinctrl@1c20800/nand-cs1-pin";
		nand_rb0_pin = "/soc/pinctrl@1c20800/nand-rb0-pin";
		nand_rb1_pin = "/soc/pinctrl@1c20800/nand-rb1-pin";
		pwm0_pin = "/soc/pinctrl@1c20800/pwm0-pin";
		spi0_pc_pins = "/soc/pinctrl@1c20800/spi0-pc-pins";
		uart0_pf_pins = "/soc/pinctrl@1c20800/uart0-pf-pins";
		uart1_pg_pins = "/soc/pinctrl@1c20800/uart1-pg-pins";
		uart1_cts_rts_pg_pins = "/soc/pinctrl@1c20800/uart1-cts-rts-pg-pins";
		uart0_pb_pins = "/soc/pinctrl@1c20800/uart0-pb-pins";
		wdt0 = "/soc/watchdog@1c20ca0";
		pwm = "/soc/pwm@1c21400";
		lradc = "/soc/lradc@1c22800";
		uart0 = "/soc/serial@1c28000";
		uart1 = "/soc/serial@1c28400";
		uart2 = "/soc/serial@1c28800";
		uart3 = "/soc/serial@1c28c00";
		uart4 = "/soc/serial@1c29000";
		i2c0 = "/soc/i2c@1c2ac00";
		touchscreen = "/soc/i2c@1c2ac00/touchscreen@40";
		i2c1 = "/soc/i2c@1c2b000";
		i2c2 = "/soc/i2c@1c2b400";
		mali = "/soc/gpu@1c40000";
		spi0 = "/soc/spi@1c68000";
		gic = "/soc/interrupt-controller@1c81000";
		fe0 = "/soc/display-frontend@1e00000";
		fe0_out = "/soc/display-frontend@1e00000/ports/port@1";
		fe0_out_be0 = "/soc/display-frontend@1e00000/ports/port@1/endpoint";
		be0 = "/soc/display-backend@1e60000";
		be0_in = "/soc/display-backend@1e60000/ports/port@0";
		be0_in_fe0 = "/soc/display-backend@1e60000/ports/port@0/endpoint";
		be0_out = "/soc/display-backend@1e60000/ports/port@1";
		be0_out_drc0 = "/soc/display-backend@1e60000/ports/port@1/endpoint";
		drc0 = "/soc/drc@1e70000";
		drc0_in = "/soc/drc@1e70000/ports/port@0";
		drc0_in_be0 = "/soc/drc@1e70000/ports/port@0/endpoint";
		drc0_out = "/soc/drc@1e70000/ports/port@1";
		drc0_out_tcon0 = "/soc/drc@1e70000/ports/port@1/endpoint";
		rtc = "/soc/rtc@1f00000";
		r_intc = "/soc/interrupt-controller@1f00c00";
		ar100 = "/soc/prcm@1f01400/ar100-clk";
		ahb0 = "/soc/prcm@1f01400/ahb0-clk";
		apb0 = "/soc/prcm@1f01400/apb0-clk";
		apb0_gates = "/soc/prcm@1f01400/apb0-gates-clk";
		apb0_rst = "/soc/prcm@1f01400/apb0-rst";
		codec_analog = "/soc/prcm@1f01400/codec-analog";
		r_uart = "/soc/serial@1f02800";
		r_i2c = "/soc/i2c@1f02400";
		r_pio = "/soc/pinctrl@1f02c00";
		r_i2c_pins = "/soc/pinctrl@1f02c00/r-i2c-pins";
		r_rsb_pins = "/soc/pinctrl@1f02c00/r-rsb-pins";
		r_uart_pins_a = "/soc/pinctrl@1f02c00/r-uart-pins";
		wifi_pwrseq_pin_q8 = "/soc/pinctrl@1f02c00/wifi-pwrseq-pins";
		r_rsb = "/soc/rsb@1f03400";
		axp22x = "/soc/rsb@1f03400/pmic@3a3";
		ac_power_supply = "/soc/rsb@1f03400/pmic@3a3/ac-power";
		axp_adc = "/soc/rsb@1f03400/pmic@3a3/adc";
		battery_power_supply = "/soc/rsb@1f03400/pmic@3a3/battery-power";
		axp_gpio = "/soc/rsb@1f03400/pmic@3a3/gpio";
		reg_dcdc1 = "/soc/rsb@1f03400/pmic@3a3/regulators/dcdc1";
		reg_dcdc2 = "/soc/rsb@1f03400/pmic@3a3/regulators/dcdc2";
		reg_dcdc3 = "/soc/rsb@1f03400/pmic@3a3/regulators/dcdc3";
		reg_dcdc4 = "/soc/rsb@1f03400/pmic@3a3/regulators/dcdc4";
		reg_dcdc5 = "/soc/rsb@1f03400/pmic@3a3/regulators/dcdc5";
		reg_dc1sw = "/soc/rsb@1f03400/pmic@3a3/regulators/dc1sw";
		reg_dc5ldo = "/soc/rsb@1f03400/pmic@3a3/regulators/dc5ldo";
		reg_aldo1 = "/soc/rsb@1f03400/pmic@3a3/regulators/aldo1";
		reg_aldo2 = "/soc/rsb@1f03400/pmic@3a3/regulators/aldo2";
		reg_aldo3 = "/soc/rsb@1f03400/pmic@3a3/regulators/aldo3";
		reg_dldo1 = "/soc/rsb@1f03400/pmic@3a3/regulators/dldo1";
		reg_dldo2 = "/soc/rsb@1f03400/pmic@3a3/regulators/dldo2";
		reg_dldo3 = "/soc/rsb@1f03400/pmic@3a3/regulators/dldo3";
		reg_dldo4 = "/soc/rsb@1f03400/pmic@3a3/regulators/dldo4";
		reg_eldo1 = "/soc/rsb@1f03400/pmic@3a3/regulators/eldo1";
		reg_eldo2 = "/soc/rsb@1f03400/pmic@3a3/regulators/eldo2";
		reg_eldo3 = "/soc/rsb@1f03400/pmic@3a3/regulators/eldo3";
		reg_ldo_io0 = "/soc/rsb@1f03400/pmic@3a3/regulators/ldo_io0";
		reg_ldo_io1 = "/soc/rsb@1f03400/pmic@3a3/regulators/ldo_io1";
		reg_rtc_ldo = "/soc/rsb@1f03400/pmic@3a3/regulators/rtc_ldo";
		reg_drivevbus = "/soc/rsb@1f03400/pmic@3a3/regulators/drivevbus";
		usb_power_supply = "/soc/rsb@1f03400/pmic@3a3/usb-power";
		crypto = "/soc/crypto-engine@1c15000";
		dai = "/soc/dai@1c22c00";
		codec = "/soc/codec@1c22e00";
		ths = "/soc/ths@1c25000";
		dsi = "/soc/dsi@1ca0000";
		dsi_in_tcon0 = "/soc/dsi@1ca0000/port/endpoint";
		dphy = "/soc/d-phy@1ca1000";
		cpu0_opp_table = "/opp-table-cpu";
		mali_opp_table = "/opp-table-gpu";
		sound = "/sound";
		link_codec = "/sound/simple-audio-card,codec";
		cpu_alert0 = "/thermal-zones/cpu-thermal/trips/cpu-alert0";
		gpu_alert0 = "/thermal-zones/cpu-thermal/trips/gpu-alert0";
		cpu_alert1 = "/thermal-zones/cpu-thermal/trips/cpu-alert1";
		gpu_alert1 = "/thermal-zones/cpu-thermal/trips/gpu-alert1";
		cpu_crit = "/thermal-zones/cpu-thermal/trips/cpu-crit";
		reg_ahci_5v = "/ahci-5v";
		reg_usb0_vbus = "/usb0-vbus";
		reg_usb1_vbus = "/usb1-vbus";
		reg_usb2_vbus = "/usb2-vbus";
		reg_vcc3v0 = "/vcc3v0";
		reg_vcc3v3 = "/vcc3v3";
		reg_vcc5v0 = "/vcc5v0";
		backlight = "/backlight";
		panel = "/panel";
		panel_input = "/panel/port/endpoint";
		wifi_pwrseq = "/pwrseq";
		binman = "/binman";
	};
};
